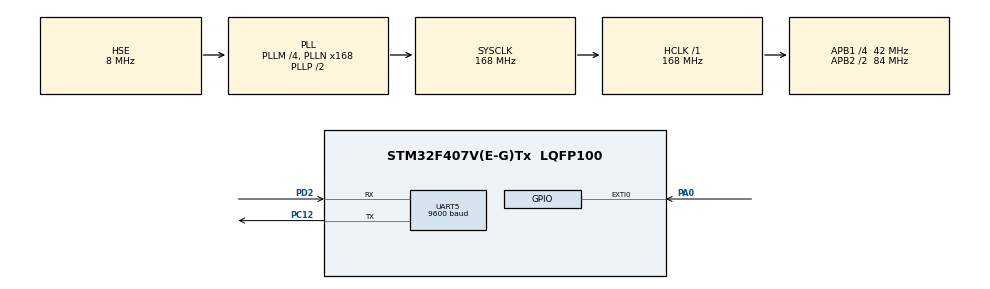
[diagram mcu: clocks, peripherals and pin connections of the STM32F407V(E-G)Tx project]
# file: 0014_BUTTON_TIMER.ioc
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Mcu.Family=STM32F4
Mcu.Name=STM32F407V(E-G)Tx
Mcu.Package=LQFP100
NVIC.EXTI0_IRQn=true\:0\:0\:false\:false\:true\:true\:true
NVIC.PriorityGroup=NVIC_PRIORITYGROUP_4
PA0-WKUP.GPIO_PuPd=GPIO_PULLDOWN
PA0-WKUP.Signal=GPXTI0
PA13.Mode=Serial_Wire
PA13.Signal=SYS_JTMS-SWDIO
PA14.Mode=Serial_Wire
PA14.Signal=SYS_JTCK-SWCLK
PC12.Mode=Asynchronous
PC12.Signal=UART5_TX
PD2.Mode=Asynchronous
PD2.Signal=UART5_RX
PH0-OSC_IN.Mode=HSE-External-Oscillator
PH0-OSC_IN.Signal=RCC_OSC_IN
PH1-OSC_OUT.Mode=HSE-External-Oscillator
PH1-OSC_OUT.Signal=RCC_OSC_OUT
ProjectManager.HeapSize=0x200
ProjectManager.StackSize=0x400
ProjectManager.TargetToolchain=TrueSTUDIO
RCC.48MHZClocksFreq_Value=84000000
RCC.AHBFreq_Value=168000000
RCC.APB1CLKDivider=RCC_HCLK_DIV4
RCC.APB1Freq_Value=42000000
RCC.APB1TimFreq_Value=84000000
RCC.APB2CLKDivider=RCC_HCLK_DIV2
RCC.APB2Freq_Value=84000000
RCC.APB2TimFreq_Value=168000000
RCC.CortexFreq_Value=168000000
RCC.HCLKFreq_Value=168000000
RCC.HSE_VALUE=8000000
RCC.HSI_VALUE=16000000
RCC.LSE_VALUE=32768
RCC.PLLM=4
RCC.PLLN=168
RCC.PLLSourceVirtual=RCC_PLLSOURCE_HSE
RCC.SYSCLKFreq_VALUE=168000000
RCC.SYSCLKSource=RCC_SYSCLKSOURCE_PLLCLK
RCC.VCOOutputFreq_Value=336000000
UART5.BaudRate=9600
UART5.VirtualMode=Asynchronous
board=custom

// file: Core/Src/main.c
/* USER CODE BEGIN Header */
/**
  ******************************************************************************
  * @file           : main.c
  * @brief          : Main program body
  ******************************************************************************
  * @attention
  *
  * <h2><center>&copy; Copyright (c) 2021 STMicroelectronics.
  * All rights reserved.</center></h2>
  *
  * This software component is licensed by ST under BSD 3-Clause license,
  * the "License"; You may not use this file except in compliance with the
  * License. You may obtain a copy of the License at:
  *                        opensource.org/licenses/BSD-3-Clause
  *
  ******************************************************************************
  */
/* USER CODE END Header */
#include "main.h"

/* USER CODE BEGIN Includes */
#include "string.h"
#include "stdio.h"
/* USER CODE END Includes */

/* USER CODE BEGIN PD */
char data[32]=" ";
int salise=0;
int saniye=0;
int dakika=0;

/* USER CODE END PD */

UART_HandleTypeDef huart5;

/* USER CODE BEGIN PV */
void uprintf(char *str)
{
    HAL_UART_Transmit(&huart5, (uint8_t*)str,strlen(str),100);
}

void sure(uint32_t time)
{
  while(time--);
}
/* USER CODE END PV */

void SystemClock_Config(void);
static void MX_GPIO_Init(void);
static void MX_UART5_Init(void);

/* USER CODE BEGIN 0 */
void HAL_GPIO_EXTI_Callback(uint16_t GPIO_Pin)
{

	sprintf(data,"\t\n\r %d Dakika, %d Saniye, %d Salise",dakika,saniye,salise);

			  uprintf(data);

	          salise=0;
	          saniye=0;
	          dakika=0;

}
/* USER CODE END 0 */

int main(void)
{

  /* MCU Configuration--------------------------------------------------------*/

  /* Reset of all peripherals, Initializes the Flash interface and the Systick. */
  HAL_Init();

  /* Configure the system clock */
  SystemClock_Config();

  /* Initialize all configured peripherals */
  MX_GPIO_Init();
  MX_UART5_Init();

  /* Infinite loop */
  while (1)
  {

    /* USER CODE BEGIN 3 */
	  while(HAL_GPIO_ReadPin(GPIOA, GPIO_PIN_0));
	  if(salise!=-1)
	  {
		  salise++;
		  HAL_Delay(16.66);

		  if(salise>=60)
		  {
			  saniye+=1;
			  salise=0;

			  if(saniye>=60)
			  {
				  dakika+=1;
				  saniye=0;
			  }
		  }

	  }
  }
  /* USER CODE END 3 */
}

void SystemClock_Config(void)
{
  RCC_OscInitTypeDef RCC_OscInitStruct = {0};
  RCC_ClkInitTypeDef RCC_ClkInitStruct = {0};

  /** Configure the main internal regulator output voltage
  */
  __HAL_RCC_PWR_CLK_ENABLE();
  __HAL_PWR_VOLTAGESCALING_CONFIG(PWR_REGULATOR_VOLTAGE_SCALE1);
  /** Initializes the RCC Oscillators according to the specified parameters
  * in the RCC_OscInitTypeDef structure.
  */
  RCC_OscInitStruct.OscillatorType = RCC_OSCILLATORTYPE_HSE;
  RCC_OscInitStruct.HSEState = RCC_HSE_ON;
  RCC_OscInitStruct.PLL.PLLState = RCC_PLL_ON;
  RCC_OscInitStruct.PLL.PLLSource = RCC_PLLSOURCE_HSE;
  RCC_OscInitStruct.PLL.PLLM = 4;
  RCC_OscInitStruct.PLL.PLLN = 168;
  RCC_OscInitStruct.PLL.PLLP = RCC_PLLP_DIV2;
  RCC_OscInitStruct.PLL.PLLQ = 4;
  if (HAL_RCC_OscConfig(&RCC_OscInitStruct) != HAL_OK)
  {
    Error_Handler();
  }
  /** Initializes the CPU, AHB and APB buses clocks
  */
  RCC_ClkInitStruct.ClockType = RCC_CLOCKTYPE_HCLK|RCC_CLOCKTYPE_SYSCLK
                              |RCC_CLOCKTYPE_PCLK1|RCC_CLOCKTYPE_PCLK2;
  RCC_ClkInitStruct.SYSCLKSource = RCC_SYSCLKSOURCE_PLLCLK;
  RCC_ClkInitStruct.AHBCLKDivider = RCC_SYSCLK_DIV1;
  RCC_ClkInitStruct.APB1CLKDivider = RCC_HCLK_DIV4;
  RCC_ClkInitStruct.APB2CLKDivider = RCC_HCLK_DIV2;

  if (HAL_RCC_ClockConfig(&RCC_ClkInitStruct, FLASH_LATENCY_5) != HAL_OK)
  {
    Error_Handler();
  }
}

static void MX_UART5_Init(void)
{

  huart5.Instance = UART5;
  huart5.Init.BaudRate = 9600;
  huart5.Init.WordLength = UART_WORDLENGTH_8B;
  huart5.Init.StopBits = UART_STOPBITS_1;
  huart5.Init.Parity = UART_PARITY_NONE;
  huart5.Init.Mode = UART_MODE_TX_RX;
  huart5.Init.HwFlowCtl = UART_HWCONTROL_NONE;
  huart5.Init.OverSampling = UART_OVERSAMPLING_16;
  if (HAL_UART_Init(&huart5) != HAL_OK)
  {
    Error_Handler();
  }

}

static void MX_GPIO_Init(void)
{
  GPIO_InitTypeDef GPIO_InitStruct = {0};

  /* GPIO Ports Clock Enable */
  __HAL_RCC_GPIOH_CLK_ENABLE();
  __HAL_RCC_GPIOA_CLK_ENABLE();
  __HAL_RCC_GPIOC_CLK_ENABLE();
  __HAL_RCC_GPIOD_CLK_ENABLE();

  /*Configure GPIO pin : PA0 */
  GPIO_InitStruct.Pin = GPIO_PIN_0;
  GPIO_InitStruct.Mode = GPIO_MODE_IT_RISING;
  GPIO_InitStruct.Pull = GPIO_PULLDOWN;
  HAL_GPIO_Init(GPIOA, &GPIO_InitStruct);

  /* EXTI interrupt init*/
  HAL_NVIC_SetPriority(EXTI0_IRQn, 0, 0);
  HAL_NVIC_EnableIRQ(EXTI0_IRQn);

}

void Error_Handler(void)
{
  __disable_irq();
  while (1)
  {
  }
}

/************************ (C) COPYRIGHT STMicroelectronics *****END OF FILE****/
